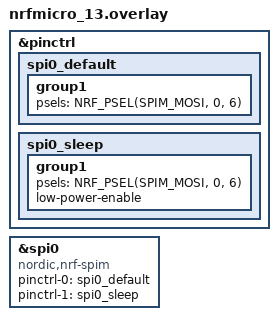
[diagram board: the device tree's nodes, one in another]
#include <dt-bindings/led/led.h>

&pinctrl {
    spi0_default: spi0_default {
        group1 {
            psels = <NRF_PSEL(SPIM_MOSI, 0, 6)>;
        };
    };

    spi0_sleep: spi0_sleep {
        group1 {
            psels = <NRF_PSEL(SPIM_MOSI, 0, 6)>;
            low-power-enable;
        };
    };
};

&spi0 {
    compatible = "nordic,nrf-spim";
    status = "okay";

    pinctrl-0 = <&spi0_default>;
    pinctrl-1 = <&spi0_sleep>;
    pinctrl-names = "default", "sleep";
};
